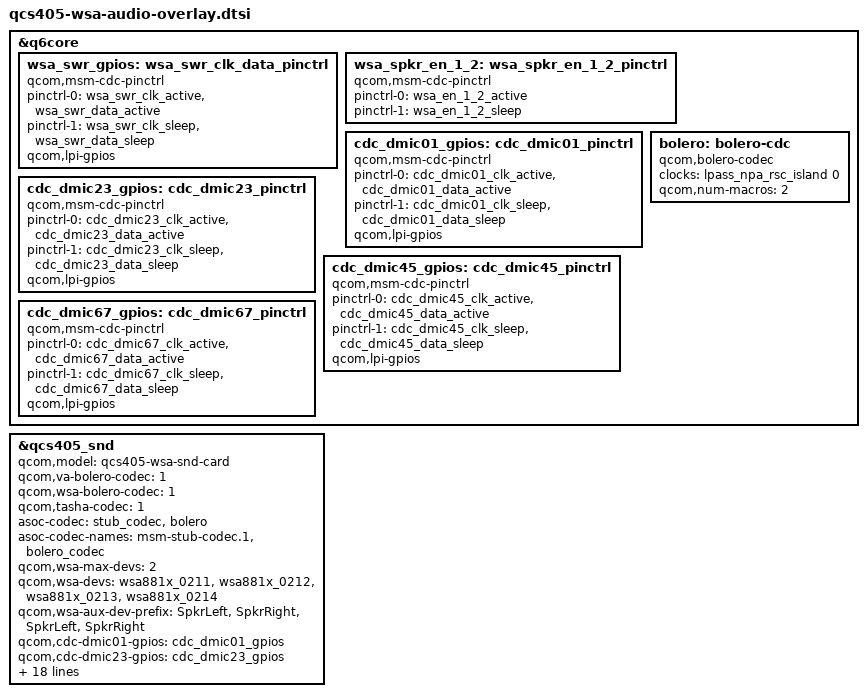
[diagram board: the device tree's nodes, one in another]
/*
 * Copyright (c) 2018, The Linux Foundation. All rights reserved.
 *
 * This program is free software; you can redistribute it and/or modify
 * it under the terms of the GNU General Public License version 2 and
 * only version 2 as published by the Free Software Foundation.
 *
 * This program is distributed in the hope that it will be useful,
 * but WITHOUT ANY WARRANTY; without even the implied warranty of
 * MERCHANTABILITY or FITNESS FOR A PARTICULAR PURPOSE.  See the
 * GNU General Public License for more details.
 */

&q6core {
	wsa_swr_gpios: wsa_swr_clk_data_pinctrl {
		compatible = "qcom,msm-cdc-pinctrl";
		pinctrl-names = "aud_active", "aud_sleep";
		pinctrl-0 = <&wsa_swr_clk_active &wsa_swr_data_active>;
		pinctrl-1 = <&wsa_swr_clk_sleep &wsa_swr_data_sleep>;
		qcom,lpi-gpios;
	};

	wsa_spkr_en_1_2: wsa_spkr_en_1_2_pinctrl {
		compatible = "qcom,msm-cdc-pinctrl";
		pinctrl-names = "aud_active", "aud_sleep";
		pinctrl-0 = <&wsa_en_1_2_active>;
		pinctrl-1 = <&wsa_en_1_2_sleep>;
	};

	cdc_dmic01_gpios: cdc_dmic01_pinctrl {
		compatible = "qcom,msm-cdc-pinctrl";
		pinctrl-names = "aud_active", "aud_sleep";
		pinctrl-0 = <&cdc_dmic01_clk_active &cdc_dmic01_data_active>;
		pinctrl-1 = <&cdc_dmic01_clk_sleep &cdc_dmic01_data_sleep>;
		qcom,lpi-gpios;
	};

	cdc_dmic23_gpios: cdc_dmic23_pinctrl {
		compatible = "qcom,msm-cdc-pinctrl";
		pinctrl-names = "aud_active", "aud_sleep";
		pinctrl-0 = <&cdc_dmic23_clk_active &cdc_dmic23_data_active>;
		pinctrl-1 = <&cdc_dmic23_clk_sleep &cdc_dmic23_data_sleep>;
		qcom,lpi-gpios;
	};

	cdc_dmic45_gpios: cdc_dmic45_pinctrl {
		compatible = "qcom,msm-cdc-pinctrl";
		pinctrl-names = "aud_active", "aud_sleep";
		pinctrl-0 = <&cdc_dmic45_clk_active &cdc_dmic45_data_active>;
		pinctrl-1 = <&cdc_dmic45_clk_sleep &cdc_dmic45_data_sleep>;
		qcom,lpi-gpios;
	};

	cdc_dmic67_gpios: cdc_dmic67_pinctrl {
		compatible = "qcom,msm-cdc-pinctrl";
		pinctrl-names = "aud_active", "aud_sleep";
		pinctrl-0 = <&cdc_dmic67_clk_active &cdc_dmic67_data_active>;
		pinctrl-1 = <&cdc_dmic67_clk_sleep &cdc_dmic67_data_sleep>;
		qcom,lpi-gpios;
	};

};

&q6core {
	bolero: bolero-cdc {
		compatible = "qcom,bolero-codec";
		clock-names = "island_lpass_npa_rsc";
		clocks = <&lpass_npa_rsc_island 0>;
		qcom,num-macros = <2>;
	};
};

&qcs405_snd {
	qcom,model = "qcs405-wsa-snd-card";
	qcom,va-bolero-codec = <1>;
	qcom,wsa-bolero-codec = <1>;
	qcom,tasha-codec = <1>;
	asoc-codec = <&stub_codec>, <&bolero>;
	asoc-codec-names = "msm-stub-codec.1", "bolero_codec";
	qcom,wsa-max-devs = <2>;
	qcom,wsa-devs = <&wsa881x_0211>, <&wsa881x_0212>,
			<&wsa881x_0213>, <&wsa881x_0214>;
	qcom,wsa-aux-dev-prefix = "SpkrLeft", "SpkrRight",
				  "SpkrLeft", "SpkrRight";
	qcom,cdc-dmic01-gpios = <&cdc_dmic01_gpios>;
	qcom,cdc-dmic23-gpios = <&cdc_dmic23_gpios>;
	qcom,cdc-dmic45-gpios = <&cdc_dmic45_gpios>;
	qcom,cdc-dmic67-gpios = <&cdc_dmic67_gpios>;
	qcom,audio-routing =
		"RX_BIAS", "MCLK",
		"AMIC3", "MIC BIAS3",
		"AMIC4", "MIC BIAS4",
		"MIC BIAS3", "Analog Mic3",
		"MIC BIAS4", "Analog Mic4",
		"VA DMIC0", "VA MIC BIAS1",
		"VA MIC BIAS1", "Digital Mic0",
		"VA DMIC1", "VA MIC BIAS1",
		"VA MIC BIAS1", "Digital Mic1",
		"VA DMIC2", "VA MIC BIAS1",
		"VA MIC BIAS1", "Digital Mic2",
		"VA DMIC3", "VA MIC BIAS1",
		"VA MIC BIAS1", "Digital Mic3",
		"VA DMIC4", "VA MIC BIAS1",
		"VA MIC BIAS1", "Digital Mic4",
		"VA DMIC5", "VA MIC BIAS1",
		"VA MIC BIAS1", "Digital Mic5",
		"VA DMIC6", "VA MIC BIAS1",
		"VA MIC BIAS1", "Digital Mic6",
		"VA DMIC7", "VA MIC BIAS1",
		"VA MIC BIAS1", "Digital Mic7",
		"SpkrLeft IN", "WSA_SPK1 OUT",
		"SpkrRight IN", "WSA_SPK2 OUT",
		"WSA_SPK1 OUT", "VA_MCLK",
		"WSA_SPK2 OUT", "VA_MCLK";
};

#include "qcs405-tasha.dtsi"
#include "qcs405-va-bolero.dtsi"
#include "qcs405-wsa-bolero.dtsi"
#include "qcs405-wsa881x.dtsi"

